# STM32F767 register map
File version: 1.7
CPU: CM7 r0p1, little endian, MPU, FPU, 4 interrupt priority bits
Registers are 32-bit, read-write, reset 0x0 unless marked. A register's access mark holds for its fields unless they carry their own. Offsets are from the block's base; [hi:lo] are bit positions.

## ADC_Common — Common ADC registers
Base 0x40012300
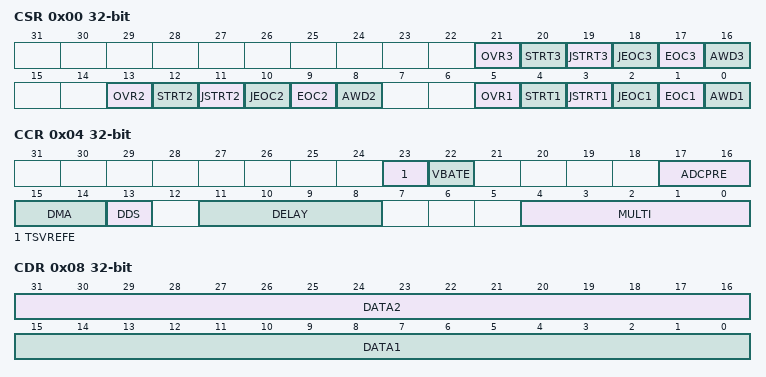
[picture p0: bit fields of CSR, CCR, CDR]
0x00 CSR ro — ADC Common status register
  [21] OVR3, [20] STRT3, [19] JSTRT3, [18] JEOC3, [17] EOC3, [16] AWD3, [13] OVR2, [12] STRT2, [11] JSTRT2, [10] JEOC2, [9] EOC2, [8] AWD2, [5] OVR1, [4] STRT1, [3] JSTRT1, [2] JEOC1, [1] EOC1, [0] AWD1
0x04 CCR — ADC common control register
  [23] TSVREFE, [22] VBATE, [17:16] ADCPRE, [15:14] DMA, [13] DDS, [11:8] DELAY, [4:0] MULTI
0x08 CDR ro — ADC common regular data register for dual and triple modes
  [31:16] DATA2, [15:0] DATA1

## DAC — Digital-to-analog converter
Base 0x40007400
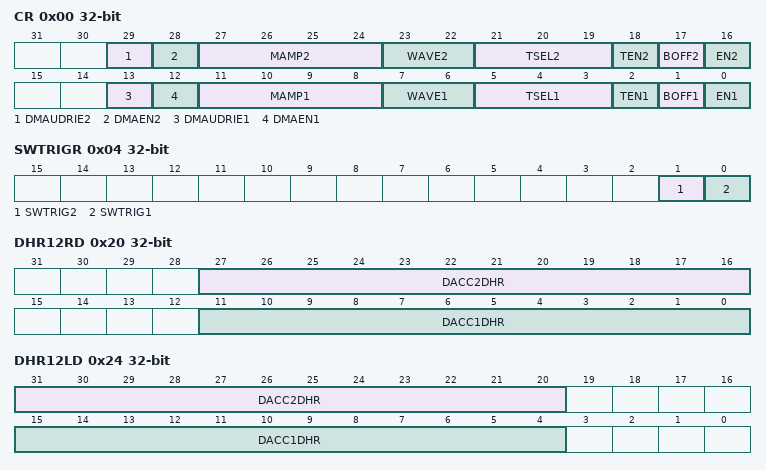
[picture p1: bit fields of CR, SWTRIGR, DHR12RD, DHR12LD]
0x00 CR — control register
  [29] DMAUDRIE2 — DAC channel2 DMA underrun interrupt enable
  [28] DMAEN2 — DAC channel2 DMA enable
  [27:24] MAMP2 — DAC channel2 mask/amplitude selector
  [23:22] WAVE2 — DAC channel2 noise/triangle wave generation enable
  [21:19] TSEL2 — DAC channel2 trigger selection
  [18] TEN2 — DAC channel2 trigger enable
  [17] BOFF2 — DAC channel2 output buffer disable
  [16] EN2 — DAC channel2 enable
  [13] DMAUDRIE1 — DAC channel1 DMA Underrun Interrupt enable
  [12] DMAEN1 — DAC channel1 DMA enable
  [11:8] MAMP1 — DAC channel1 mask/amplitude selector
  [7:6] WAVE1 — DAC channel1 noise/triangle wave generation enable
  [5:3] TSEL1 — DAC channel1 trigger selection
  [2] TEN1 — DAC channel1 trigger enable
  [1] BOFF1 — DAC channel1 output buffer disable
  [0] EN1 — DAC channel1 enable
0x04 SWTRIGR wo — software trigger register
  [1] SWTRIG2 — DAC channel2 software trigger
  [0] SWTRIG1 — DAC channel1 software trigger
0x08 DHR12R1 — channel1 12-bit right-aligned data holding register
  [11:0] DACC1DHR — DAC channel1 12-bit right-aligned data
0x0C DHR12L1 — channel1 12-bit left aligned data holding register
  [15:4] DACC1DHR — DAC channel1 12-bit left-aligned data
0x10 DHR8R1 — channel1 8-bit right aligned data holding register
  [7:0] DACC1DHR — DAC channel1 8-bit right-aligned data
0x14 DHR12R2 — channel2 12-bit right aligned data holding register
  [11:0] DACC2DHR — DAC channel2 12-bit right-aligned data
0x18 DHR12L2 — channel2 12-bit left aligned data holding register
  [15:4] DACC2DHR — DAC channel2 12-bit left-aligned data
0x1C DHR8R2 — channel2 8-bit right-aligned data holding register
  [7:0] DACC2DHR — DAC channel2 8-bit right-aligned data
0x20 DHR12RD — Dual DAC 12-bit right-aligned data holding register
  [27:16] DACC2DHR — DAC channel2 12-bit right-aligned data
  [11:0] DACC1DHR — DAC channel1 12-bit right-aligned data
0x24 DHR12LD — DUAL DAC 12-bit left aligned data holding register
  [31:20] DACC2DHR — DAC channel2 12-bit left-aligned data
  [15:4] DACC1DHR — DAC channel1 12-bit left-aligned data
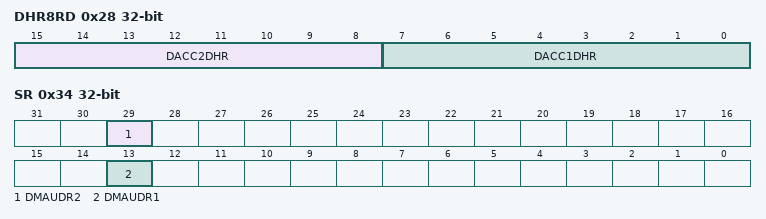
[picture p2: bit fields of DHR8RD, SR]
0x28 DHR8RD — DUAL DAC 8-bit right aligned data holding register
  [15:8] DACC2DHR — DAC channel2 8-bit right-aligned data
  [7:0] DACC1DHR — DAC channel1 8-bit right-aligned data
0x2C DOR1 ro — channel1 data output register
  [11:0] DACC1DOR — DAC channel1 data output
0x30 DOR2 ro — channel2 data output register
  [11:0] DACC2DOR — DAC channel2 data output
0x34 SR — status register
  [29] DMAUDR2 — DAC channel2 DMA underrun flag
  [13] DMAUDR1 — DAC channel1 DMA underrun flag

## PWR — Power control
Base 0x40007000
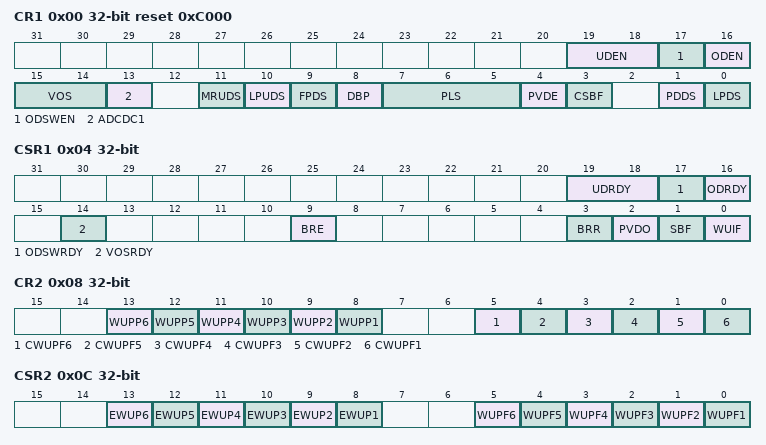
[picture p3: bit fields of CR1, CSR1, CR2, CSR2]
0x00 CR1 reset 0xC000 — power control register
  [19:18] UDEN — Under-drive enable in stop mode
  [17] ODSWEN — Over-drive switching enabled
  [16] ODEN — Over-drive enable
  [15:14] VOS — Regulator voltage scaling output selection
  [13] ADCDC1
  [11] MRUDS — Main regulator in deepsleep under-drive mode
  [10] LPUDS — Low-power regulator in deepsleep under-drive mode
  [9] FPDS — Flash power down in Stop mode
  [8] DBP — Disable backup domain write protection
  [7:5] PLS — PVD level selection
  [4] PVDE — Power voltage detector enable
  [3] CSBF — Clear standby flag
  [1] PDDS — Power down deepsleep
  [0] LPDS — Low-power deep sleep
0x04 CSR1 access per field — power control/status register
  [19:18] UDRDY rw — Under-drive ready flag
  [17] ODSWRDY ro — Over-drive mode switching ready
  [16] ODRDY ro — Over-drive mode ready
  [14] VOSRDY ro — Regulator voltage scaling output selection ready bit
  [9] BRE rw — Backup regulator enable
  [3] BRR ro — Backup regulator ready
  [2] PVDO ro — PVD output
  [1] SBF ro — Standby flag
  [0] WUIF ro — Wakeup internal flag
0x08 CR2 access per field — power control register
  [13] WUPP6 rw — Wakeup pin polarity bit for PI11
  [12] WUPP5 rw — Wakeup pin polarity bit for PI8
  [11] WUPP4 rw — Wakeup pin polarity bit for PC13
  [10] WUPP3 rw — Wakeup pin polarity bit for PC1
  [9] WUPP2 rw — Wakeup pin polarity bit for PA2
  [8] WUPP1 rw — Wakeup pin polarity bit for PA0
  [5] CWUPF6 ro — Clear Wakeup Pin flag for PI11
  [4] CWUPF5 ro — Clear Wakeup Pin flag for PI8
  [3] CWUPF4 ro — Clear Wakeup Pin flag for PC13
  [2] CWUPF3 ro — Clear Wakeup Pin flag for PC1
  [1] CWUPF2 ro — Clear Wakeup Pin flag for PA2
  [0] CWUPF1 ro — Clear Wakeup Pin flag for PA0
0x0C CSR2 access per field — power control/status register
  [13] EWUP6 rw — Enable Wakeup pin for PI11
  [12] EWUP5 rw — Enable Wakeup pin for PI8
  [11] EWUP4 rw — Enable Wakeup pin for PC13
  [10] EWUP3 rw — Enable Wakeup pin for PC1
  [9] EWUP2 rw — Enable Wakeup pin for PA2
  [8] EWUP1 rw — Enable Wakeup pin for PA0
  [5] WUPF6 ro — Wakeup Pin flag for PI11
  [4] WUPF5 ro — Wakeup Pin flag for PI8
  [3] WUPF4 ro — Wakeup Pin flag for PC13
  [2] WUPF3 ro — Wakeup Pin flag for PC1
  [1] WUPF2 ro — Wakeup Pin flag for PA2
  [0] WUPF1 ro — Wakeup Pin flag for PA0
